VERSION "dbc-export 1 2026.26.6.5"

NS_ :

BS_:

BU_: APP DAS PARK

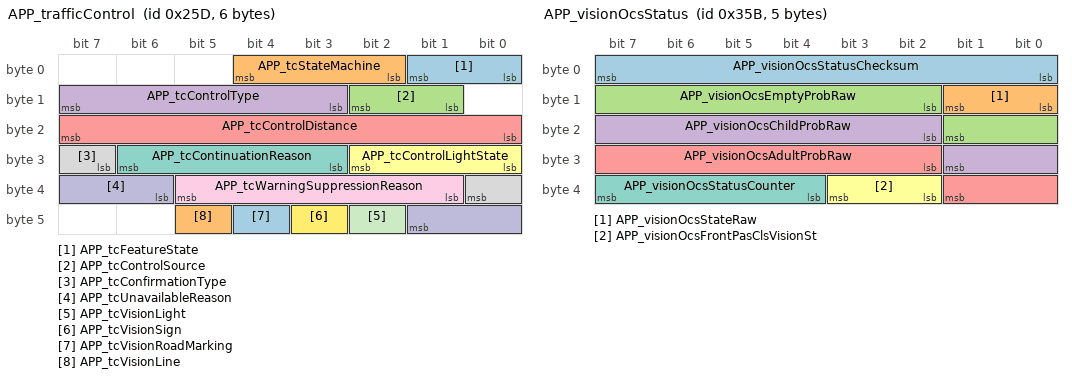
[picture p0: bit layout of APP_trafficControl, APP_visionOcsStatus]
BO_ 605 APP_trafficControl: 6 APP
 SG_ APP_tcFeatureState : 0|2@1+ (1,0) [0|3] "" Vector__XXX
 SG_ APP_tcStateMachine : 2|3@1+ (1,0) [0|7] "" Vector__XXX
 SG_ APP_tcControlSource : 9|2@1+ (1,0) [0|3] "" Vector__XXX
 SG_ APP_tcControlType : 11|5@1+ (1,0) [0|31] "" Vector__XXX
 SG_ APP_tcControlDistance : 16|8@1+ (1,0) [0|254] "m" Vector__XXX
 SG_ APP_tcControlLightState : 24|3@1+ (1,0) [0|7] "" Vector__XXX
 SG_ APP_tcContinuationReason : 27|4@1+ (1,0) [0|15] "" Vector__XXX
 SG_ APP_tcConfirmationType : 31|2@1+ (1,0) [0|3] "" Vector__XXX
 SG_ APP_tcWarningSuppressionReason : 33|5@1+ (1,0) [0|31] "" Vector__XXX
 SG_ APP_tcUnavailableReason : 38|4@1+ (1,0) [0|15] "" Vector__XXX
 SG_ APP_tcVisionLight : 42|1@1+ (1,0) [0|1] "" Vector__XXX
 SG_ APP_tcVisionSign : 43|1@1+ (1,0) [0|1] "" Vector__XXX
 SG_ APP_tcVisionRoadMarking : 44|1@1+ (1,0) [0|1] "" Vector__XXX
 SG_ APP_tcVisionLine : 45|1@1+ (1,0) [0|1] "" Vector__XXX

BO_ 859 APP_visionOcsStatus: 5 APP
 SG_ APP_visionOcsStatusChecksum : 0|8@1+ (1,0) [0|255] "" Vector__XXX
 SG_ APP_visionOcsStateRaw : 8|2@1+ (1,0) [0|3] "" Vector__XXX
 SG_ APP_visionOcsEmptyProbRaw : 10|8@1+ (0.004,0) [0|1.016] "points" Vector__XXX
 SG_ APP_visionOcsChildProbRaw : 18|8@1+ (0.004,0) [0|1.016] "points" Vector__XXX
 SG_ APP_visionOcsAdultProbRaw : 26|8@1+ (0.004,0) [0|1.016] "points" Vector__XXX
 SG_ APP_visionOcsFrontPasClsVisionSt : 34|2@1+ (1,0) [0|3] "" Vector__XXX
 SG_ APP_visionOcsStatusCounter : 36|4@1+ (1,0) [0|15] "" Vector__XXX

BO_ 401 DAS_autonomyDebugInfo: 2 DAS
 SG_ DAS_autonomyUnavailableReason : 2|9@1+ (1,0) [0|511] "" Vector__XXX

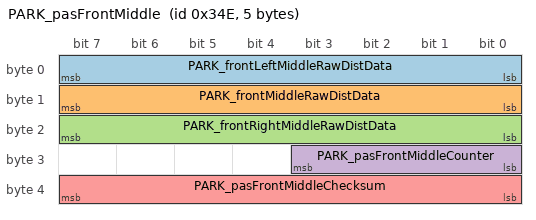
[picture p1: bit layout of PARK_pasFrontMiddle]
BO_ 846 PARK_pasFrontMiddle: 5 PARK
 SG_ PARK_frontLeftMiddleRawDistData : 0|8@1+ (1,0) [0|254] "cm" Vector__XXX
 SG_ PARK_frontMiddleRawDistData : 8|8@1+ (1,0) [0|254] "cm" Vector__XXX
 SG_ PARK_frontRightMiddleRawDistData : 16|8@1+ (1,0) [0|254] "cm" Vector__XXX
 SG_ PARK_pasFrontMiddleCounter : 24|4@1+ (1,0) [0|15] "" Vector__XXX
 SG_ PARK_pasFrontMiddleChecksum : 32|8@1+ (1,0) [0|255] "" Vector__XXX

BO_TX_BU_ 605 : APP;
BO_TX_BU_ 859 : APP;
BO_TX_BU_ 401 : DAS;
BO_TX_BU_ 846 : PARK;

CM_ "Tesla Bayberry CAN bus database; bus CH (chassis CAN); firmware 2026.26.6.5. Decoded CAN signal definitions (layout, scaling, units, value tables).";
CM_ BU_ APP "Driver assistance computer (primary)";
CM_ BU_ DAS "Driver assistance computer";
CM_ BU_ PARK "Parking assist sensors";
CM_ BO_ 605 "Driver assistance computer (primary) message: traffic control; frame length from the layout, not yet observed on a vehicle bus";
CM_ SG_ 605 APP_tcFeatureState "The feature level state of stopping for traffic controls";
CM_ SG_ 605 APP_tcStateMachine "The traffic control state machine's internal control state.";
CM_ SG_ 605 APP_tcControlSource "The input data source for the traffic control object";
CM_ SG_ 605 APP_tcControlType "The specific type of traffic control, note not all are control worthy.";
CM_ SG_ 605 APP_tcControlDistance "The distance to the nearest critical traffic control object; raw 255 = signal not available (SNA)";
CM_ SG_ 605 APP_tcControlLightState "Driver assistance computer (primary): tc control light state";
CM_ SG_ 605 APP_tcContinuationReason "The reason the traffic control state machine entered the continue state.";
CM_ SG_ 605 APP_tcConfirmationType "The mechanism of how the driver confirmed the traffic control.";
CM_ SG_ 605 APP_tcWarningSuppressionReason "The suppression reason for the traffic control warning feature.";
CM_ SG_ 605 APP_tcUnavailableReason "The reason why the traffic control feature is currently unavailable.";
CM_ SG_ 605 APP_tcVisionLight "Whether or not the traffic light has a vision measurement.";
CM_ SG_ 605 APP_tcVisionSign "Whether or not the traffic sign has a vision measurement.";
CM_ SG_ 605 APP_tcVisionRoadMarking "Whether or not the road marking has a vision measurement.";
CM_ SG_ 605 APP_tcVisionLine "Whether or not the traffic control line has a vision measurement.";
CM_ BO_ 859 "Driver assistance computer (primary) message: vision ocs status; frame length from the layout, not yet observed on a vehicle bus";
CM_ SG_ 859 APP_visionOcsStatusChecksum "Driver assistance computer (primary): vision ocs status checksum";
CM_ SG_ 859 APP_visionOcsStateRaw "Reports classification state raw signal for front passenger from interior camera.";
CM_ SG_ 859 APP_visionOcsEmptyProbRaw "Driver assistance computer (primary): vision ocs empty prob raw; raw 255 = signal not available (SNA)";
CM_ SG_ 859 APP_visionOcsChildProbRaw "Driver assistance computer (primary): vision ocs child prob raw; raw 255 = signal not available (SNA)";
CM_ SG_ 859 APP_visionOcsAdultProbRaw "Driver assistance computer (primary): vision ocs adult prob raw; raw 255 = signal not available (SNA)";
CM_ SG_ 859 APP_visionOcsFrontPasClsVisionSt "Reports classification state of front passenger seat after Bayesian filter.";
CM_ SG_ 859 APP_visionOcsStatusCounter "Driver assistance computer (primary): vision ocs status counter";
CM_ BO_ 401 "Driver assistance computer message: autonomy debug info; frame length from the layout, not yet observed on a vehicle bus";
CM_ SG_ 401 DAS_autonomyUnavailableReason "Reports the reason for Autonomy being unavailable";
CM_ BO_ 846 "Parking assist sensors message: pas front middle; frame length from the layout, not yet observed on a vehicle bus";
CM_ SG_ 846 PARK_frontLeftMiddleRawDistData "Zone defined as -38 degrees -> +12 degrees, distance to object in units of centimeters; raw 255 = signal not available (SNA)";
CM_ SG_ 846 PARK_frontMiddleRawDistData "Zone defined as -12 degrees to +12 degrees, distance to object in units of centimeters; raw 255 = signal not available (SNA)";
CM_ SG_ 846 PARK_frontRightMiddleRawDistData "Zone defined +12 degrees to +38 degreees, distance to object in units of centimeters; raw 255 = signal not available (SNA)";
CM_ SG_ 846 PARK_pasFrontMiddleCounter "Parking assist sensors: pas front middle counter";
CM_ SG_ 846 PARK_pasFrontMiddleChecksum "Parking assist sensors: pas front middle checksum";
BA_DEF_ "BusType" STRING;
BA_DEF_ "DBName" STRING;
BA_DEF_ "Baudrate" INT 0 1000000;
BA_DEF_ "BaudrateCANFD" INT 0 16000000;
BA_DEF_ "Manufacturer" STRING;
BA_DEF_ "FirmwareVersion" STRING;
BA_DEF_ "VehicleModel" STRING;
BA_DEF_ BU_ "ECU" STRING;
BA_DEF_ BO_ "GenMsgCycleTime" INT 0 3600000;
BA_DEF_ BO_ "GenMsgSendType" ENUM "Cyclic","NotUsed","NotUsed","NotUsed","NotUsed","NotUsed","NotUsed","IfActive","NoMsgSendType","NotUsed";
BA_DEF_ BO_ "VFrameFormat" ENUM "StandardCAN","ExtendedCAN","reserved","J1939PG","reserved","reserved","reserved","reserved","reserved","reserved","reserved","reserved","reserved","reserved","StandardCAN_FD","ExtendedCAN_FD";
BA_DEF_ BO_ "CANFD_BRS" ENUM "0","1";
BA_DEF_ SG_ "GenSigSNA" STRING;
BA_DEF_ SG_ "SystemSignalLongSymbol" STRING;
BA_DEF_ SG_ "Confidence" ENUM "validated","plausible","layout-only","contradicted";
BA_DEF_DEF_ "BusType" "CAN";
BA_DEF_DEF_ "DBName" "";
BA_DEF_DEF_ "Baudrate" 500000;
BA_DEF_DEF_ "BaudrateCANFD" 2000000;
BA_DEF_DEF_ "Manufacturer" "";
BA_DEF_DEF_ "FirmwareVersion" "";
BA_DEF_DEF_ "VehicleModel" "";
BA_DEF_DEF_ "ECU" "";
BA_DEF_DEF_ "GenMsgCycleTime" 0;
BA_DEF_DEF_ "GenMsgSendType" "NoMsgSendType";
BA_DEF_DEF_ "VFrameFormat" "StandardCAN";
BA_DEF_DEF_ "CANFD_BRS" "1";
BA_DEF_DEF_ "GenSigSNA" "";
BA_DEF_DEF_ "SystemSignalLongSymbol" "";
BA_DEF_DEF_ "Confidence" "layout-only";
BA_ "DBName" "Bayberry_CH";
BA_ "Manufacturer" "Tesla";
BA_ "FirmwareVersion" "2026.26.6.5";
BA_ "VehicleModel" "Bayberry";
BA_ "ECU" BU_ APP "APP";
BA_ "ECU" BU_ DAS "DAS";
BA_ "ECU" BU_ PARK "PARK";
BA_ "GenMsgCycleTime" BO_ 605 500;
BA_ "GenMsgSendType" BO_ 605 0;
BA_ "GenMsgCycleTime" BO_ 859 100;
BA_ "GenMsgSendType" BO_ 859 0;
BA_ "GenMsgCycleTime" BO_ 401 100;
BA_ "GenMsgSendType" BO_ 401 0;
BA_ "GenMsgCycleTime" BO_ 846 100;
BA_ "GenMsgSendType" BO_ 846 0;
BA_ "Confidence" SG_ 605 APP_tcFeatureState 0;
BA_ "Confidence" SG_ 605 APP_tcStateMachine 0;
BA_ "Confidence" SG_ 605 APP_tcControlSource 0;
BA_ "Confidence" SG_ 605 APP_tcControlType 0;
BA_ "Confidence" SG_ 605 APP_tcControlDistance 0;
BA_ "GenSigSNA" SG_ 605 APP_tcControlDistance "255";
BA_ "Confidence" SG_ 605 APP_tcControlLightState 0;
BA_ "Confidence" SG_ 605 APP_tcContinuationReason 0;
BA_ "Confidence" SG_ 605 APP_tcConfirmationType 0;
BA_ "Confidence" SG_ 605 APP_tcWarningSuppressionReason 0;
BA_ "Confidence" SG_ 605 APP_tcUnavailableReason 0;
BA_ "Confidence" SG_ 605 APP_tcVisionLight 0;
BA_ "Confidence" SG_ 605 APP_tcVisionSign 0;
BA_ "Confidence" SG_ 605 APP_tcVisionRoadMarking 0;
BA_ "Confidence" SG_ 605 APP_tcVisionLine 0;
BA_ "Confidence" SG_ 859 APP_visionOcsStatusChecksum 0;
BA_ "Confidence" SG_ 859 APP_visionOcsStateRaw 0;
BA_ "Confidence" SG_ 859 APP_visionOcsEmptyProbRaw 0;
BA_ "GenSigSNA" SG_ 859 APP_visionOcsEmptyProbRaw "255";
BA_ "Confidence" SG_ 859 APP_visionOcsChildProbRaw 0;
BA_ "GenSigSNA" SG_ 859 APP_visionOcsChildProbRaw "255";
BA_ "Confidence" SG_ 859 APP_visionOcsAdultProbRaw 0;
BA_ "GenSigSNA" SG_ 859 APP_visionOcsAdultProbRaw "255";
BA_ "Confidence" SG_ 859 APP_visionOcsFrontPasClsVisionSt 0;
BA_ "SystemSignalLongSymbol" SG_ 859 APP_visionOcsFrontPasClsVisionSt "APP_visionOcsFrontPasClsVisionStateFlt";
BA_ "Confidence" SG_ 859 APP_visionOcsStatusCounter 0;
BA_ "Confidence" SG_ 401 DAS_autonomyUnavailableReason 0;
BA_ "Confidence" SG_ 846 PARK_frontLeftMiddleRawDistData 0;
BA_ "GenSigSNA" SG_ 846 PARK_frontLeftMiddleRawDistData "255";
BA_ "Confidence" SG_ 846 PARK_frontMiddleRawDistData 0;
BA_ "GenSigSNA" SG_ 846 PARK_frontMiddleRawDistData "255";
BA_ "Confidence" SG_ 846 PARK_frontRightMiddleRawDistData 0;
BA_ "GenSigSNA" SG_ 846 PARK_frontRightMiddleRawDistData "255";
BA_ "Confidence" SG_ 846 PARK_pasFrontMiddleCounter 0;
BA_ "Confidence" SG_ 846 PARK_pasFrontMiddleChecksum 0;
VAL_ 605 APP_tcFeatureState 3 "TC_ACTIVE" 2 "TC_AVAILABLE" 1 "TC_UNAVAILABLE" 0 "TC_DISABLED" ;
VAL_ 605 APP_tcStateMachine 6 "TCSM_CONTINUING" 5 "TCSM_STOPPED" 4 "TCSM_STOPPING" 3 "TCSM_WARNING" 2 "TCSM_AWARE" 1 "TCSM_STANDBY" 0 "TCSM_DISABLED" ;
VAL_ 605 APP_tcControlSource 3 "TC_SOURCE_MAP_AND_VISION" 2 "TC_SOURCE_VISION" 1 "TC_SOURCE_MAP" 0 "TC_SOURCE_NONE" ;
VAL_ 605 APP_tcControlType 22 "TC_TYPE_T_ARM" 21 "TC_TYPE_BEV_JUNCTION" 20 "TC_TYPE_T_IMPLICIT_BY_GEOM" 19 "TC_TYPE_T_IMPLICIT_BY_NAME" 18 "TC_TYPE_T_IMPLICIT" 17 "TC_TYPE_NO_STOP" 16 "TC_TYPE_BIKE_MERGE_FROM_RIGHT" 15 "TC_TYPE_BIKE_MERGE_FROM_LEFT" 14 "TC_TYPE_ALL_WAY_STOP_SIGN" 13 "TC_TYPE_TRAFFIC_RULE" 12 "TC_TYPE_SPEED_HUMP" 11 "TC_TYPE_SPEED_BUMP" 10 "TC_TYPE_RAMP_METER" 9 "TC_TYPE_PEDESTRIAN_CROSSING" 8 "TC_TYPE_SUICIDE_LEFT" 7 "TC_TYPE_KEEP_CLEAR_EXIT" 6 "TC_TYPE_KEEP_CLEAR_ENTER" 5 "TC_TYPE_CROSSWALK" 4 "TC_TYPE_YIELD" 3 "TC_TYPE_TRAFFIC_LIGHT" 2 "TC_TYPE_STOP_SIGN" 1 "TC_TYPE_UNKNOWN" 0 "TC_TYPE_INVALID" ;
VAL_ 605 APP_tcControlDistance 255 "SNA" ;
VAL_ 605 APP_tcControlLightState 6 "TC_LIGHTSTATE_OTHER" 5 "TC_LIGHTSTAET_WHITE" 4 "TC_LIGHTSTATE_OFF" 3 "TC_LIGHTSTATE_YELLOW" 2 "TC_LIGHTSTATE_GREEN" 1 "TC_LIGHTSTATE_RED" 0 "TC_LIGHTSTATE_NONE" ;
VAL_ 605 APP_tcContinuationReason 13 "TC_CONTINUE_CONTROL_UNAVAILABLE" 12 "TC_CONTINUE_SUMMON_TIMEOUT" 11 "TC_CONTINUE_CLEAR_TO_GO" 10 "TC_CONTINUE_WARNING_TIMEOUT" 9 "TC_CONTINUE_INVALID_MAP_OR_VISION_CONTROL" 8 "TC_CONTINUE_PASSED_STOP" 7 "TC_CONTINUE_ASSUMED_DRIVER_STOPPED" 6 "TC_CONTINUE_AP_ACTIVATED_ON_HARD_STOP" 5 "TC_CONTINUE_VISION_SIGNALS" 4 "TC_CONTINUE_REQUIRED_DECEL_TOO_HIGH" 3 "TC_CONTINUE_USER_INPUT_ON_RED" 2 "TC_CONTINUE_USER_INPUT_ON_GREEN" 1 "TC_CONTINUE_GREEN_LIGHT_WITH_CIPV" 0 "TC_CONTINUE_NONE" ;
VAL_ 605 APP_tcConfirmationType 2 "TC_CONFIRM_PEDAL" 1 "TC_CONFIRM_STALK" 0 "TC_CONFIRM_NONE" ;
VAL_ 605 APP_tcWarningSuppressionReason 18 "TC_WARNING_SUPPRESS_TOO_FAR_FROM_PREDICTED_JUNCTION" 17 "TC_WARNING_SUPPRESS_NOT_SUPPORTED_BY_MEASUREMENTS" 16 "TC_WARNING_SUPPRESS_NO_ASSOCIATED_VISION_LINE" 15 "TC_WARNING_SUPPRESS_AMBIGUOUS_VISION_TYPE" 14 "TC_WARNING_SUPPRESS_CIPV_DID_NOT_STOP" 13 "TC_WARNING_SUPPRESS_STALE_SIGN_DETECTION" 12 "TC_WARNING_SUPPRESS_WRONG_MAP_TYPE" 11 "TC_WARNING_SUPPRESS_LIGHT_UNASSOCIATED" 10 "TC_WARNING_SUPPRESS_CIPV_CONTINUING" 9 "TC_WARNING_SUPPRESS_PEDAL_OVERRIDE" 8 "TC_WARNING_SUPPRESS_LOCALIZATION_DEGRADED" 7 "TC_WARNING_SUPPRESS_HARD_TURN" 6 "TC_WARNING_SUPPRESS_ASSUMED_YELLOW" 5 "TC_WARNING_SUPPRESS_DRIVER_SLOWING_DOWN" 4 "TC_WARNING_SUPPRESS_BELOW_MIN_SPEED" 3 "TC_WARNING_SUPPRESS_SLOWDOWN_PLANNED" 2 "TC_WARNING_SUPPRESS_INSUFFICIENT_DATA" 1 "TC_WARNING_SUPPRESS_FEATURE_DISABLED" 0 "TC_WARNING_SUPPRESS_NONE" ;
VAL_ 605 APP_tcUnavailableReason 9 "AP_UNAVAILBLE_SUN_GLARE_ON_ROAD_RESTRICTED" 8 "AP_UNAVAILBLE_CAMERA_BLINDED_ON_ROAD_RESTRICTED" 7 "AP_UNAVAILBLE_GPS_DEGRADED" 6 "AP_UNAVAILBLE_ROAD_ESTIMATOR_UNHEALTHY" 5 "AP_UNAVAILBLE_SUN_GLARE" 4 "AP_UNAVAILBLE_CAMERA_BLINDED" 3 "AP_UNAVAILBLE_ROAD_CLASS" 2 "AP_UNAVAILBLE_LOST_MAP_LOCALIZATION" 1 "AP_UNAVAILBLE_MCU_DISABLED" 0 "AP_UNAVAILBLE_NONE" ;
VAL_ 859 APP_visionOcsStateRaw 3 "ADULT" 2 "CHILD" 1 "EMPTY" 0 "UNKNOWN" ;
VAL_ 859 APP_visionOcsEmptyProbRaw 255 "SNA" ;
VAL_ 859 APP_visionOcsChildProbRaw 255 "SNA" ;
VAL_ 859 APP_visionOcsAdultProbRaw 255 "SNA" ;
VAL_ 859 APP_visionOcsFrontPasClsVisionSt 3 "ADULT" 2 "CHILD" 1 "EMPTY" 0 "UNKNOWN" ;
VAL_ 401 DAS_autonomyUnavailableReason 414 "TRAJECTORY_ON_PUBLIC_ROAD_NOT_INDOORS" 413 "STOP_IN_LANE_NOT_HONORED" 412 "SIMPLE_SUMMON_OBSTACLE_BLOCKED" 411 "SEVERE_SINGLE_FRONT_VISION_OCCLUSION_AFTER_WIPE" 410 "PHONE_TOO_FAR_TO_START" 409 "MAX_SPEED_LIMIT_FOR_MODE_EXCEEDED" 408 "EPB_REDUNDANT_BRAKING_UNAVAILABLE" 407 "EGO_GEAR_NOT_ALLOWED" 406 "EGO_EXCEEDED_MAX_SUMMON_DISTANCE" 405 "DUAL_EPB_UNAVAILABLE" 404 "COMPRESSOR_FRAME_DROP_RATE_HIGH" 403 "CAN_RX_VALIDATION_ERROR" 402 "BRAKE_APPLIED_PARKED" 401 "ALARM_ACTIVE" 400 "SAFETY_DRIVER_UNBUCKLED_PRE_ACTIVATION" 399 "NOT_FACTORY_SCHEDULE" 398 "FSD_REGION_NOT_ALLOWED" 397 "FSD_QUIZ_REQUIRED" 396 "EPAS_EAC_NOT_ACTIVE_OTHER" 395 "EPAS_EAC_NOT_ACTIVE_HANDS_ON" 394 "DI_CONTROL_INTEGRATOR_WINDUP" 393 "SEVERE_SINGLE_FRONT_VISION_OCCLUSION_HIGH_FOGGING_RISK" 392 "EGO_NEAR_SUMMON_MAP_BOUNDARY_NOT_INDOORS" 391 "GOAL_NEAR_SUMMON_MAP_BOUNDARY_NOT_INDOORS" 390 "GRADE_TOO_HIGH_WITHOUT_REDUNDANT_BRAKING_LOW_MU" 389 "NAV_DESTINATION_OUTSIDE_GEOFENCE" 388 "RCM_COLLISION_SEVERITY_TRIGGERED" 387 "EPB_PARKING_AVAILABILITY_TOO_STEEP" 386 "REVERSE_GEAR_NOT_AVAILABLE" 385 "DESTINATION_OUTSIDE_GEOFENCE_AP" 384 "SSD_CLIP_LOGGING_CRITICAL" 383 "DRIVE_GEAR_NOT_AVAILABLE" 382 "SIDE_VISIBILITY_DEGRADED_PARKED_DOORS_CLOSED" 381 "PERSISTENT_FRAME_DROPS" 380 "PERSISTENT_HANDS_ON_NOT_ALLOWED" 379 "NAV_ROUTE_EXCEEDS_GEOFENCE_BUFFER" 378 "RANKER_OUTPUT_STALE" 377 "VISION_PLANNER_STALE" 376 "AUTO_WIPERS_OFF" 375 "COUNTRY_NOT_ALLOWED_FOR_OPERATION" 374 "OUTSIDE_TRACK_TEST_GEOFENCE" 373 "TEMPERATURE_EXCEEDS_ODD" 372 "RIDESHARE_NAV_GOAL_NOT_IN_SYNC" 371 "HV_BATTERY_AC_CHARGING_UNHEALTHY" 370 "HV_BATTERY_DC_CHARGING_UNHEALTHY" 369 "UI_RIDE_SETUP_IN_PROGRESS" 368 "AUTO_HEADLIGHTS_OFF" 367 "IMMOBILIZER_AUTH_AUTONOMY" 366 "DI_RESTRICTED_DRIVING_MANUAL_RECOVERY" 365 "SUMMON_ACTIVE_DURATION_EXCEEDED" 364 "ESKF_SPEED_SOURCE_ACTIVE" 363 "IMU_DATA_NOT_RELIABLE_WITH_FLEET_CONFIG_ENABLED" 362 "FASCIA_VISION_OCCLUSION_AT_LONG_STOP" 361 "HIGH_SPEED_ROAD_ON_ROUTE" 360 "EGO_ON_HIGH_SPEED_ROAD" 359 "UNACCOMPANIED_UNDERAGE_RIDER_DETECTED" 358 "AEB_FAULTED" 357 "AUDIO_HARDWARE_ODIN_FAILED" 356 "FASCIA_VISION_FAILSAFE_PARKED" 355 "APS_B_EPLANNER_NO_VALID_TRAJECTORY" 354 "APS_A_EPLANNER_NO_VALID_TRAJECTORY" 353 "FASCIA_CAM_INTEGRATED_HEATER_FAULT" 352 "BACKUP_CAM_INTEGRATED_HEATER_FAULT" 351 "RIGHT_REPEATER_CAM_INTEGRATED_HEATER_FAULT" 350 "LEFT_REPEATER_CAM_INTEGRATED_HEATER_FAULT" 349 "RIGHT_PILLAR_CAM_INTEGRATED_HEATER_FAULT" 348 "LEFT_PILLAR_CAM_INTEGRATED_HEATER_FAULT" 347 "RIGHT_PILLAR_CAM_WIRE_HEATER_FAULT" 346 "LEFT_PILLAR_CAM_WIRE_HEATER_FAULT" 345 "WINDSHIELD_CAM_WIRE_HEATER_FAULT" 344 "CONTROLLER_EPLANNER_UNHEALTHY" 343 "VEHICLE_COLLISION_DETECTED" 342 "VRU_COLLISION_DETECTED" 341 "MAJOR_COLLISION_DETECTED" 340 "ONGOING_COLLISION_DETECTED" 339 "INTEGRATOR_ACCELERATION_INVALID" 338 "CABIN_CAM_DRIVER_MONITORING_SYSTEM_UNAVAILABLE" 337 "DCAS_DRIVER_ATTENTION_STATE_DETERMINATION_DEGRADED" 336 "NON_MAIN_FRONT_CAMERAS_STREAM_LOST" 335 "MAIN_CAMERA_STREAM_LOST" 334 "DRIVER_WIPER_WASH_HEALTH_DEGRADED" 333 "EPB_AUTONOMY_BEHAVIOR_MISMATCH" 332 "DI_AUTONOMY_BEHAVIOR_MISMATCH" 331 "VC_AUTONOMY_BEHAVIOR_MISMATCH" 330 "DCAS_EXITED_REGION_TIMEOUT" 329 "WASHER_PUMP_NOT_HEALTHY" 328 "AP_B_SOC_UNHEALTHY" 327 "RCM_AIR_BAG_DEPLOY" 326 "RCM_NEAR_DEPLOY" 325 "AP_A_SOC_UNHEALTHY" 324 "ROUTE_EXCEEDS_SPEED_LIMIT" 323 "PERSISTENT_INVALID_NAV_ROUTE" 322 "NAV_ROUTE_EXITS_GEOFENCE" 321 "NAV_AVOID_HIGH_SPEED_ROADS_DISABLED" 320 "NAV_WHITELIST_ROUTING_DISABLED" 319 "NAV_ROUTE_RANKER_DISABLED" 318 "NAV_AVOID_SHORT_LANE_CHANGE_DISABLED" 317 "NAV_AVOID_UNPROTECTED_TURN_DISABLED" 316 "HIGHWAY_ON_ROUTE" 315 "EGO_ON_HIGHWAY" 314 "INVALID_VEHICLE_OPERATION_MODE" 313 "STEERING_ANGLE_OFFSET_HIGH" 312 "SAFETY_DRIVER_INATTENTIVE" 311 "TRACK_MODE_ACTIVE" 310 "EXT_TEMP_LOW_CERAMIC_BRAKES" 309 "GOAL_NEAR_SUMMON_MAP_BOUNDARY" 308 "SUMMON_HEARTBEAT_MISSING" 307 "EGO_NEAR_SUMMON_MAP_BOUNDARY" 306 "EGO_OUTSIDE_SUMMON_MAP_RADIUS" 305 "SUMMON_MAP_INVALID" 304 "RAW_UI_SUMMON_GOAL_INVALID" 303 "SUMMON_GOAL_INVALID" 302 "SYSTEM_CDP_UNAVAILABLE" 301 "SUMMON_COLLISION_DETECTION_ACTIVE" 300 "PHONE_TOO_FAR" 299 "PHONE_GPS_INVALID" 298 "GRADE_TOO_HIGH_WITHOUT_REDUNDANT_BRAKING" 297 "CABIN_CAM_DRIVER_MONITORING_UNAVAILABLE" 296 "CABIN_CAMERA_STREAM_FAILURE" 295 "DRIVER_PRESENCE_VISION_UNAVAILABLE" 294 "PEDAL_OVERRIDE_EXCEEDS_CONTROLLER_LIMITS" 293 "UPCOMING_FERRY_CROSSING" 292 "DRIVER_PARTIALLY_OCCLUDED" 291 "DRIVER_REQUIREMENTS_NOT_MET_VC" 290 "DRIVER_AGE_REQUIREMENTS_NOT_MET_VISION" 289 "GPS_DEGRADED" 288 "PILLARS_SWAP_DETECTED" 287 "NARROW_FISHEYE_SWAP_DETECTED" 286 "SCCM_MIA" 285 "RECENT_STALK_GEAR_SHIFT" 284 "IBOOSTER_MIA" 283 "PARKING_SPOT_SELECTED" 282 "SCROLL_WHEEL_INTERACTION" 281 "PEDAL_OVERRIDE_STRIKEOUT_FOR_DRIVE" 280 "PEDAL_OVERRIDE_STRIKEOUT" 279 "ABOVE_MAX_ACTIVATION_SPEED" 278 "DRIVER_MONITOR_SUSPENSION_ACTIVE" 277 "DRIVER_MONITOR_STRUCK_OUT_FOR_DRIVE" 276 "VC_CAMERA_AIR_CLEANING_STATUS_MIA" 275 "VC_CAMERA_FLUID_CLEANING_STATUS_MIA" 274 "INVALID_DI_PEDAL_POS" 273 "CABIN_CAMERA_FAN_RPM_FAULT" 272 "SELF_NETWORK_DECRYPTION_NOT_READY" 271 "OFF_ROAD_MODE_ACTIVE" 270 "SSD_CLIP_LOGGING_INACTIVE" 269 "CAMERA_EXPOSURE_INACTIVE" 268 "CAMERA_EXPOSURE_MISMATCH" 267 "CABIN_CAMERA_IR_LED_FAULTED" 266 "TAMPERING_DETECTED" 265 "NO_IMU_SOURCES_AVAILABLE" 264 "IMU_REDUNDANCY_LOST" 263 "DI_AUTONOMY_HEALTH_CAN_MESSAGE_MIA" 262 "ALL_WHEEL_SPEEDS_SENSORS_FAULTED" 261 "WHEEL_SPEEDS_CAN_MESSAGE_MIA" 260 "AP_THERMAL_MODEL_FAULT_DETECTED" 259 "SGK_AUTONOMY_MODE_NOT_IN_SYNC" 258 "SGK_AUTONOMY_STATE_NOT_IN_SYNC" 257 "ANY_RIGHT_DOOR_OPEN_BUTTON_FAULTED" 256 "ANY_LEFT_DOOR_OPEN_BUTTON_FAULTED" 255 "VCRIGHT_DOOR_STATUS_CAN_MESSAGE_MIA" 254 "VCLEFT_DOOR_STATUS_CAN_MESSAGE_MIA" 253 "BB_STATUS_CAN_MESSAGE_MIA" 252 "GTW_CAR_CONFIG_CAN_MESSAGE_MIA" 251 "TRAILER_MODE_ACTIVE" 250 "UI_LIMIT_MODE_ACTIVE" 249 "UI_QT_CAR_UNAVAILABLE" 248 "UI_CONNECTIVITY_HW_UNHEALTHY" 247 "UI_CONNECTIVITY_OFFLINE" 246 "UI_CENTER_DISPLAY_UNAVAILABLE" 245 "UI_HEALTH_STATUS_CAN_MESSAGE_MIA" 244 "ANY_LV_HEALTH_CAN_MESSAGE_INVALID" 243 "ANY_LV_HEALTH_CAN_MESSAGE_MIA" 242 "AP_SYSTEM_ISSUE_PENDING_REBOOT" 241 "AP_TASK_PENDING_REBOOT" 240 "APS_DUAL_CAMERA_POWER_FAILURE" 239 "APS_SINGLE_CAMERA_POWER_FAILURE" 238 "APS_ETH_BRIDGE_DOWN" 237 "APS_PEER_PMIC_FAULTED" 236 "APS_SELF_PMIC_FAULTED" 235 "APS_PEER_VRM_FAULTED" 234 "APS_SELF_VRM_FAULTED" 233 "APS_PEER_IMEM_FAULTED" 232 "APS_SELF_IMEM_FAULTED" 231 "APS_PEER_CAN_FAULTED" 230 "APS_SELF_CAN_FAULTED" 229 "APS_B_UNHEALTHY" 228 "APS_A_UNHEALTHY" 227 "PEER_VISION_FAILOVER_ACTIVE" 226 "ARBITER_SELECTED_BEHAVIOR_OUT_OF_DATE" 225 "ARBITER_SELECTED_BEHAVIOR_NOT_E2E" 224 "MISSION_PLANNER_DESIRED_BEHAVIOR_NOT_E2E" 223 "AUTONOMY_CONTROLLING_AND_NOT_PARKED" 222 "NO_VALID_SGK_STATUS" 221 "AUTONOMOUS_BEHAVIORS_LINK_NOT_ESTABLISHED" 220 "GNSS_PPS_MIA" 219 "GNSS_ANTENNA_DISCONNECTED" 218 "GNSS_UART_FAULTED" 217 "AP_THERMAL_DEGRADED_PULLOVER_REQ" 216 "AP_THERMAL_DEGRADED_BLOCK_ACTIVATION" 215 "DRIVER_PRESENT_NOT_ALLOWED" 214 "UNSUPERVISED_OPERATION_NOT_ALLOWED" 213 "NOT_IN_RT_NO_TAKEOVER_FLEET" 212 "SAFETY_OPERATOR_NOT_PRESENT" 211 "CAMERA_PRECONDITIONING_REQUIRED" 210 "BMS_CAN_MESSAGES_MIA" 209 "VEHICLE_LOSING_HV" 208 "HV_DRIVE_NO_RESTART" 207 "AUTONOMOUS_BEHAVIORS_TASK_SUSPENDING" 206 "AUDIO_BUS_DOWN" 205 "CAMERA_REDUNDANCY_NOT_READY" 204 "NO_VEHICLE_SPEED_SOURCE_AVAILABLE" 203 "DI_PRIMARY_SPEED_SOURCE_UNAVAILABLE" 202 "DI_SPEED_CAN_MESSAGE_MIA" 201 "DEFOG_SYSTEM_UNHEALTHY" 200 "COOLANT_SYSTEM_UNHEALTHY" 199 "DEFOG_SYSTEM_NOT_READY" 198 "COOLANT_SYSTEM_NOT_READY" 197 "NOT_AUTHENTICATED_FOR_DRIVE" 196 "UNASSIGNED_PASSENGER_UNBUCKLED" 195 "WAITING_FOR_PASSENGER_EGRESS" 194 "PASSENGER_UNEXPECTED_RIDE_INACTIVE" 193 "DRIVER_NOT_PRESENT_PRE_ACTIVATION" 192 "NARROW_WASH_NOT_AVAILABLE" 191 "REDUNDANT_IMU_CAN_MESSAGES_MIA" 190 "IMU_CAN_MESSAGES_MIA" 189 "BRAKING_CAN_MESSAGES_MIA" 188 "EPB_AUTONOMY_CAN_MESSAGES_MIA" 187 "PARK_BRAKE_CAN_MESSAGES_MIA" 186 "STEERING_CAN_MESSAGES_MIA" 185 "DI_SYSTEM_STATUS_CAN_MESSAGES_MIA" 184 "DI_CHASSIS_CONTROL_CAN_MESSAGE_MIA" 183 "APS_CAN_MESSAGES_MIA" 182 "POOR_LOCALIZATION_ACCURACY" 181 "VISION_FAILOVER_ACTIVE" 180 "SEAT_OCCUPANCY_STATUS_UNHEALTHY" 179 "TO_STREAMS_UNHEALTHY" 178 "SEATBELT_STATUS_UNHEALTHY" 177 "RCM_WARNING_INDICATOR_ON" 176 "REDUNDANT_BRAKES_FAIL_OPERATIONAL" 175 "REDUNDANT_BRAKES_REDUNDANCY_LOST" 174 "REDUNDANT_BRAKES_NOT_ARMED" 173 "REDUNDANT_BRAKES_NOT_READY" 172 "REDUNDANT_BRAKE_PATH_ACTIVE" 171 "RANKER_NOT_HEALTHY" 170 "PARKED_A_PEDAL_PRESSED" 169 "ANY_CANCEL_ACTIVE" 168 "BRAKE_CONFIRM_PENDING_PARK" 167 "BRAKE_APPLIED_D_R_N" 166 "BRAKE_RELEASE_PENDING_PARK" 165 "ENFORCED_UNPARK_DELAY_ACTIVE" 164 "WIPER_NOT_HEALTHY" 163 "RIGHT_PILLAR_CAM_HEATER_FAULT" 162 "LEFT_PILLAR_CAM_HEATER_FAULT" 161 "WINDSHIELD_CAM_HEATER_FAULT" 160 "ALL_TAIL_LIGHTS_FAULTED_IN_LOW_VIS" 159 "TAIL_LIGHT_FAULTED" 158 "REVERSE_LIGHT_FAULTED" 157 "RIGHT_TURN_LIGHT_FAULTED" 156 "LEFT_TURN_LIGHT_FAULTED" 155 "ALL_BRAKE_LIGHTS_FAULTED" 154 "BRAKE_LIGHT_FAULTED" 153 "HIGH_BEAM_LIGHT_FAULTED_IN_LOW_VIS" 152 "LOW_BEAM_LIGHT_FAULTED_IN_LOW_VIS" 151 "HIGH_BEAM_LIGHT_FAULTED" 150 "LOW_BEAM_LIGHT_FAULTED" 149 "HEADLIGHTS_NOT_AIMED" 148 "HEADLIGHTS_OFF_AT_NIGHT" 147 "AP_REDUNDANCY_UNAVAILABLE" 146 "DI_BRAKING_DECELERATION_UNAVAILABLE" 145 "DI_VDC_ACTIVE" 144 "DI_TC_ACTIVE" 143 "DI_VDC_STATE_NOT_NORMAL" 142 "DI_LOSING_PROPULSION" 141 "EPB_STATUS_NOT_PARKED" 140 "EPB_PARKING_AVAILABILITY_UNKNOWN" 139 "EPB_PARKING_AVAILABILITY_REQUEST_PATH_DEGRADED" 138 "EPB_PARKING_AVAILABILITY_SPEED_INVALID" 137 "EPB_PARKING_AVAILABILITY_FAULTED" 136 "TIRE_PRESSURE_SENSOR_FAULT" 135 "FLAT_TIRE" 134 "INTEGRATOR_HEALTH_CRITICAL" 133 "IMU_DATA_NOT_RELIABLE" 132 "FASCIA_FLUID_CLEAN_CRITICAL" 131 "BACKUP_FLUID_CLEAN_CRITICAL" 130 "RIGHT_REPEATER_FLUID_CLEAN_CRITICAL" 129 "LEFT_REPEATER_FLUID_CLEAN_CRITICAL" 128 "FASCIA_AIR_CLEAN_CRITICAL" 127 "BACKUP_AIR_CLEAN_CRITICAL" 126 "RIGHT_REPEATER_AIR_CLEAN_CRITICAL" 125 "LEFT_REPEATER_AIR_CLEAN_CRITICAL" 124 "FASCIA_FLUID_CLEAN_DEGRADED" 123 "BACKUP_FLUID_CLEAN_DEGRADED" 122 "RIGHT_REPEATER_FLUID_CLEAN_DEGRADED" 121 "LEFT_REPEATER_FLUID_CLEAN_DEGRADED" 120 "FASCIA_AIR_CLEAN_DEGRADED" 119 "BACKUP_AIR_CLEAN_DEGRADED" 118 "RIGHT_REPEATER_AIR_CLEAN_DEGRADED" 117 "LEFT_REPEATER_AIR_CLEAN_DEGRADED" 116 "TERTIARY_WASHER_FLUID_LOW" 115 "SECONDARY_WASHER_FLUID_LOW" 114 "WASHER_FLUID_LOW" 113 "ELEVATED_TIRE_PRESSURE_READING" 112 "LOW_TIRE_PRESSURE_READING" 111 "VISION_CABIN_OCCUPANCY_UNAVAILABLE" 110 "SGK_AUTOSTEER_MONITOR_ACTIVE" 109 "SGK_PLANNER_ACTIVE_D_R_N" 108 "FLEET_MAINTENANCE_EXPIRING_SOON" 107 "FLEET_MAINTENANCE_REQUIRED" 106 "CHARGE_CABLE_CONNECTED_OR_STATUS_UNKNOWN" 105 "PASSENGER_UNBUCKLED_ACTIVE_RIDE" 104 "PASSENGER_UNBUCKLED" 103 "SYSTEM_UNHEALTHY_DEV_OVERRIDE" 102 "SINGLE_SOC_HEALTHY_EXCEPTION" 101 "IMU_REPLICATION_NOT_READY" 100 "STATE_MACHINE_DISABLED" 99 "INCOMPATIBLE_SYSTEM_HEALTH" 98 "CABIN_CAM_BLINDED" 97 "RIDESHARE_INGRESS_NO_NAV_ROUTE" 96 "PASSENGER_EXPECTED" 95 "DRIVER_MONITOR_STRIKEOUT" 94 "DRIVER_NOT_PRESENT" 93 "CONTROLLER_SOLVER_CRITICAL" 92 "CONTROLLER_SOLVER_DEGRADED" 91 "CONTROLLER_DEGRADED_PEDAL_OVERRIDE" 90 "CONTROLLER_SOLVER_FAILURE" 89 "LV_CRITICAL_STATE" 88 "LV_DEGRADED_STATE" 87 "VEHICLE_AUTONOMY_BEHAVIOR_MISMATCH" 86 "CRUISE_STACK_MISMATCH" 85 "EPB_REDUNDANT_BRAKING_STATUS" 84 "EXTENDED_COMPUTE_INACTIVE_OTHER" 83 "EXTENDED_COMPUTE_TIME_SYNC_CRITICAL_DEGRADED" 82 "EXTENDED_COMPUTE_OTHER_SOC_STATE_UNKNOWN" 81 "EXTENDED_COMPUTE_OTHER_SOC_STATE_INACTIVE" 80 "EXTENDED_COMPUTE_PCIE_LINK_HEALTH" 79 "EXTENDED_COMPUTE_ETHERNET_LINK_HEALTH" 78 "EXTENDED_COMPUTE_OTHER_SOC_HEALTH_CRITICAL" 77 "EXTENDED_COMPUTE_OTHER_SOC_HEALTH_UNKNOWN" 76 "EXTENDED_COMPUTE_SOC_HEALTH_CRITICAL" 75 "EXTENDED_COMPUTE_SOC_HEALTH_UNKNOWN" 74 "FSD_FROM_PARK_DISABLED" 73 "NOT_IN_PARK_NO_TAKEOVER" 72 "NO_FIXED_ROUTE" 71 "NAV_GOAL_INVALID" 70 "ANY_EPAS_FAULT" 69 "EPAS_SYSTEM_TORQUE_REDUCED" 68 "EPAS_SECONDARY_MASTER" 67 "EPAS_REDUNDANCY_LOST" 66 "EPAS_DRIVERLESS_MODE_NOT_ACTIVE" 65 "EPAS_EAC_NOT_ACTIVE" 64 "EPAS_EAC_UNAVAILABLE" 63 "STEERING_ANGLE_INVALID" 62 "CRUISE_FAULT" 61 "CRUISE_NOT_ACTIVE_OTHER" 60 "CRUISE_NOT_ACTIVE_ESTOP" 59 "CRUISE_UNAVAILABLE_OTHER" 58 "CRUISE_UNAVAILABLE_BRAKE_APPLIED" 57 "NOT_POWER_STATE_DRIVE" 56 "FRUNK_OPEN" 55 "TRUNK_OPEN" 54 "PASSENGER_DOOR_OPEN" 53 "DRIVER_DOOR_OPEN" 52 "VISION_FPS_LOW_CAMERA_DROPS" 51 "VISION_LATENCY_HIGH" 50 "SAFETY_DRIVER_UNBUCKLED" 49 "FASCIA_VISION_OCCLUSION_AT_STOP" 48 "SEVERE_RIGHT_VISION_OCCLUSION_REVERSE" 47 "SEVERE_LEFT_VISION_OCCLUSION_REVERSE" 46 "SEVERE_BACKUP_VISION_OCCLUSION_REVERSE" 45 "SEVERE_RIGHT_VISION_OCCLUSION_MANEUVER" 44 "SEVERE_LEFT_VISION_OCCLUSION_MANEUVER" 43 "SEVERE_RIGHT_VISION_OCCLUSION" 42 "SEVERE_LEFT_VISION_OCCLUSION" 41 "SEVERE_MULTIPLE_FRONT_VISION_OCCLUSION" 40 "SEVERE_SINGLE_FRONT_VISION_OCCLUSION" 39 "CAMERA_HEALTH_METRICS_UNHEALTHY" 38 "VISION_SCENETAGS_UNHEALTHY" 37 "VISION_AUTOWIPER_UNHEALTHY" 36 "VISION_AUTOHIGHBEAM_UNHEALTHY" 35 "VISION_FAILSAFES_UNHEALTHY" 34 "RIGHT_VISION_FAILSAFE_PARKED" 33 "LEFT_VISION_FAILSAFE_PARKED" 32 "FRONT_VISION_FAILSAFE_PARKED" 31 "REAR_VISION_FAILSAFE_PARKED" 30 "CAMERA_OFFGASSING" 29 "CAMERA_OFFGASSING_PRE_ALERT" 28 "INTERMITTENT_FRAME_DROPS" 27 "CAMERA_AUTOEXPOSURE_LOST" 26 "OUT_OF_SYNC_CAMERA_STREAMS" 25 "FASCIA_CAMERA_STREAM_LOST" 24 "BACKUP_CAMERA_STREAM_LOST" 23 "RIGHT_CAMERAS_STREAM_LOST" 22 "LEFT_CAMERAS_STREAM_LOST" 21 "FRONT_CAMERAS_STREAM_LOST" 20 "CAMERA_MCU_FW_MISMATCH" 19 "FACTORY_CALIBRATION" 18 "CAMERA_PITCH_OUT_OF_BOUNDS" 17 "CAMERA_CALIBRATION" 16 "GNSS_DEGRADED_SIGNAL_STRENGTH" 15 "AP_POWER_REQUEST_NOT_NOMINAL" 14 "SENTRY_ACTIVE" 13 "NO_REDUNDANT_BRAKING" 12 "HK_RESTRICTED" 11 "OUTSIDE_GEOFENCE" 10 "RUN_MODE_NOT_FSD" 9 "AEB_ACTIVE" 8 "SUMMON_ACTIVE" 7 "AUTOPARK_ACTIVE" 6 "FSD_DISABLED" 5 "CAR_WASH_MODE" 4 "DELIVERED" 3 "NO_AUTONOMY_MODE_ACTIVE" 2 "NEUTRAL_GEAR" 1 "NONE" 0 "UNKNOWN" ;
VAL_ 846 PARK_frontLeftMiddleRawDistData 255 "SNA" ;
VAL_ 846 PARK_frontMiddleRawDistData 255 "SNA" ;
VAL_ 846 PARK_frontRightMiddleRawDistData 255 "SNA" ;
